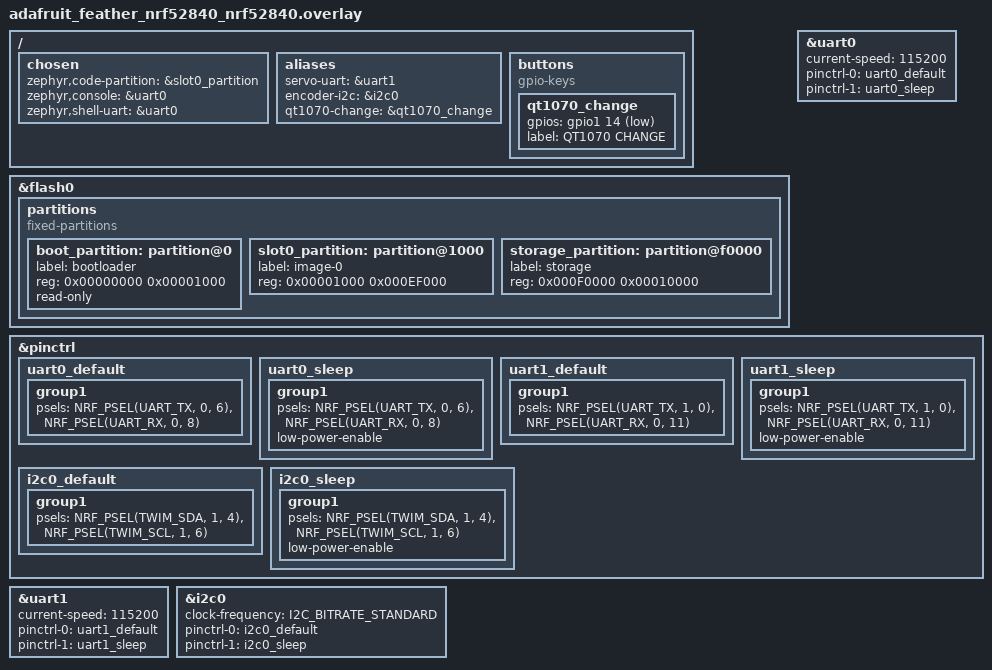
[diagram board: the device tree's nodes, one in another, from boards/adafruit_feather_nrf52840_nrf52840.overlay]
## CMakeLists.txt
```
cmake_minimum_required(VERSION 3.20.0)
find_package(Zephyr REQUIRED HINTS $ENV{ZEPHYR_BASE})
project(follower)

target_sources(app PRIVATE 
    src/main.c
    src/i2c_devices.c
    src/follower_transport.c
    src/controller_follower_protocol.cpp
)

include_directories(
    ${CMAKE_SOURCE_DIR}/inc
)
```

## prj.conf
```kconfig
# ---- Logging ----
CONFIG_LOG=y
CONFIG_LOG_BACKEND_UART=y
CONFIG_UART_CONSOLE=y
CONFIG_CONSOLE=y
CONFIG_LOG_MODE_IMMEDIATE=y

# ---- FPU -----
CONFIG_FPU=y
CONFIG_FPU_SHARING=y

# ---- Serial / UART ----
CONFIG_SERIAL=y
CONFIG_UART_ASYNC_API=y
CONFIG_UART_ASYNC_RX_HELPER=y
CONFIG_UART_LINE_CTRL=y
CONFIG_UART_INTERRUPT_DRIVEN=y
CONFIG_UART_0_INTERRUPT_DRIVEN=y
CONFIG_UART_1_INTERRUPT_DRIVEN=y

# ---- Bluetooth core ----
CONFIG_BT=y
CONFIG_BT_PERIPHERAL=y
CONFIG_BT_DEVICE_NAME="Follower"
CONFIG_BT_DEVICE_APPEARANCE=0

# ---- Nordic UART Service ----
CONFIG_BT_NUS=y

# ---- Buffer tuning ----
CONFIG_BT_BUF_ACL_TX_SIZE=251
CONFIG_BT_BUF_ACL_RX_SIZE=251
CONFIG_BT_L2CAP_TX_MTU=247
CONFIG_BT_BUF_ACL_TX_COUNT=3
CONFIG_BT_ATT_PREPARE_COUNT=4

# ---- Kernel ----
CONFIG_HEAP_MEM_POOL_SIZE=2048
CONFIG_MAIN_STACK_SIZE=2048
CONFIG_SYSTEM_WORKQUEUE_STACK_SIZE=2048

# ---- Devicetree ----
CONFIG_USE_DT_CODE_PARTITION=y

# ---- I2C ----
CONFIG_I2C=y

# ---- GPIO ----
CONFIG_GPIO=y

# ---- MISC ---- 
CONFIG_PRINTK_SYNC=y
```

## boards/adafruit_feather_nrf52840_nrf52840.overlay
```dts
/*
 * nice!nano / Feather nRF52840 Express — application overlay
 */

/* ---- 1. Flash partition table ---- */
/delete-node/ &boot_partition;
/delete-node/ &slot0_partition;
/delete-node/ &slot1_partition;
/delete-node/ &storage_partition;

/ {
    chosen {
        zephyr,code-partition = &slot0_partition;
        zephyr,console        = &uart0;
        zephyr,shell-uart     = &uart0;
    };

    aliases {
        servo-uart = &uart1;
        encoder-i2c = &i2c0;
    };
};

&flash0 {
    partitions {
        compatible = "fixed-partitions";
        #address-cells = <1>;
        #size-cells = <1>;
        ranges;

        boot_partition: partition@0 {
            label = "bootloader";
            reg = <0x00000000 0x00001000>;
            read-only;
        };

        slot0_partition: partition@1000 {
            label = "image-0";
            reg = <0x00001000 0x000EF000>;
        };

        storage_partition: partition@f0000 {
            label = "storage";
            reg = <0x000F0000 0x00010000>;
        };
    };
};

/* ---- 2. Hardware UART0 on D0/D1 (P0.08 RX / P0.06 TX) for logging ---- */
&uart0 {
    status = "okay";
    current-speed = <115200>;
    pinctrl-0 = <&uart0_default>;
    pinctrl-1 = <&uart0_sleep>;
    pinctrl-names = "default", "sleep";
};

&pinctrl {
    uart0_default: uart0_default {
        group1 {
            psels = <NRF_PSEL(UART_TX, 0, 6)>,
                    <NRF_PSEL(UART_RX, 0, 8)>;
        };
    };
    uart0_sleep: uart0_sleep {
        group1 {
            psels = <NRF_PSEL(UART_TX, 0, 6)>,
                    <NRF_PSEL(UART_RX, 0, 8)>;
            low-power-enable;
        };
    };
};

&uart1 {
    status = "okay";
    current-speed = <115200>;
    pinctrl-0 = <&uart1_default>;
    pinctrl-1 = <&uart1_sleep>;
    pinctrl-names = "default", "sleep";
};

&pinctrl {
    uart1_default: uart1_default {
        group1 {
            psels = <NRF_PSEL(UART_TX, 1, 0)>,
                    <NRF_PSEL(UART_RX, 0, 11)>;
        };
    };
    uart1_sleep: uart1_sleep {
        group1 {
            psels = <NRF_PSEL(UART_TX, 1, 0)>,
                    <NRF_PSEL(UART_RX, 0, 11)>;
            low-power-enable;
        };
    };
};

/* ---- Hardware I2C0 on P0.20 (SDA) / P0.22 (SCL) for mag encoders/touch---- */
&i2c0 {
    status = "okay";
    clock-frequency = <I2C_BITRATE_STANDARD>;
    pinctrl-0 = <&i2c0_default>;
    pinctrl-1 = <&i2c0_sleep>;
    pinctrl-names = "default", "sleep";
};

&pinctrl {
    i2c0_default: i2c0_default {
        group1 {
            psels = <NRF_PSEL(TWIM_SDA, 1, 4)>,
                    <NRF_PSEL(TWIM_SCL, 1, 6)>;
        };
    };
    i2c0_sleep: i2c0_sleep {
        group1 {
            psels = <NRF_PSEL(TWIM_SDA, 1, 4)>,
                    <NRF_PSEL(TWIM_SCL, 1, 6)>;
            low-power-enable;
        };
    };
};


/ {
    buttons {
        compatible = "gpio-keys";
        qt1070_change: qt1070_change {
            gpios = <&gpio1 14 (GPIO_PULL_UP | GPIO_ACTIVE_LOW)>;
            label = "QT1070 CHANGE";
        };
    };
    aliases {
        qt1070-change = &qt1070_change;
    };
};
```

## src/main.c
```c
#include <zephyr/kernel.h>
#include <zephyr/device.h>
#include <zephyr/drivers/uart.h>
#include <zephyr/drivers/gpio.h>
#include <zephyr/logging/log.h>
#include <zephyr/bluetooth/bluetooth.h>
#include <zephyr/bluetooth/conn.h>
#include <zephyr/bluetooth/gap.h>
#include <bluetooth/services/nus.h>
#include <stdio.h>
#include "i2c_devices.h"
#include "math.h"
#include "controller_follower_protocol.h"
#include "follower_transport.h"

LOG_MODULE_REGISTER(main, LOG_LEVEL_INF);

/* ---------------  Prototype declarations ------- */
static void lx16a_send_packet(uint8_t id, uint8_t len, uint8_t cmd, uint8_t ahb, uint8_t alb, uint16_t time);

/* ---------------- Hardware UART ---------------- */
#define UART_DEVICE_NODE DT_CHOSEN(zephyr_console)
static const struct device *uart_dev = DEVICE_DT_GET(DT_ALIAS(servo_uart));

#define UART_BUF_SIZE 256
static uint8_t uart_rx_buf[UART_BUF_SIZE];

static void uart_cb(const struct device *dev, struct uart_event *evt, void *user_data);
#define NUM_SERVOS    5

/* ---------------- UART callback ---------------- */
static void uart_cb(const struct device *dev, struct uart_event *evt, void *user_data)
{
    switch (evt->type) {
    case UART_RX_RDY:
        if(bt_is_ready()){
            LOG_INF("UART RX %d bytes", evt->data.rx.len);
            bt_nus_send(NULL, &evt->data.rx.buf[evt->data.rx.offset], evt->data.rx.len);
        }
        break;

    case UART_RX_BUF_REQUEST:
        uart_rx_buf_rsp(dev, uart_rx_buf, sizeof(uart_rx_buf));
        break;

    case UART_RX_BUF_RELEASED:
        break;

    case UART_TX_DONE:
        break;

    case UART_TX_ABORTED:
        LOG_WRN("UART TX aborted");
        break;

    default:
        break;
    }
}

/* ---------------- QT1070 CHANGE PIN ---------------- */
static const struct gpio_dt_spec qt_change = GPIO_DT_SPEC_GET(DT_ALIAS(qt1070_change), gpios);

static struct gpio_callback qt_cb;

static void qt_change_handler(const struct device *port,
                              struct gpio_callback *cb, uint32_t pins)
{
    uint8_t detection = 0;
    qt1070_read_status(&detection, NULL);
    LOG_INF("Touch interrupt: 0x%02X", detection);
}

/* ---------------- BLE NUS callbacks ---------------- */
static void nus_receive_cb(struct bt_conn *conn,
                            const uint8_t *data,
                            uint16_t len)
{
    ARG_UNUSED(conn);
    if (len < offsetof(protocol_frame_t, payload)) {
        printk("NUS RX: short frame (%u)\n", len);
        return;
    }

    protocol_frame_t frame;
    memset(&frame, 0, sizeof(frame));

    /* Copy the header */
    memcpy(&frame, data, offsetof(protocol_frame_t, payload));

    if (frame.start_byte != PROTO_START_BYTE) {
        printk("NUS RX: bad start byte 0x%02X\n", frame.start_byte);
        return;
    }
    if (frame.payload_length > PROTO_MAX_PAYLOAD_SIZE) {
        printk("NUS RX: payload too long (%u)\n", frame.payload_length);
        return;
    }

    size_t expected = frame_total_size(&frame);
    if (len < expected) {
        printk("NUS RX: truncated frame (got %u, need %u)\n",
               len, (unsigned)expected);
        return;
    }

    /* Copy payload and CRC */
    memcpy(frame.payload, data + offsetof(protocol_frame_t, payload),
           frame.payload_length);
    memcpy(&frame.crc,
           data + offsetof(protocol_frame_t, payload) + frame.payload_length,
           sizeof(frame.crc));

    if (!frame_verify_crc(&frame)) {
        printk("NUS RX: CRC mismatch\n");
        return;
    }

    if (frame.type != MSG_COMMAND_SERVO) {
        printk("NUS RX: unexpected type 0x%02X\n", frame.type);
        return;
    }
    if (frame.payload_length < sizeof(servo_command_payload_t)) {
        printk("NUS RX: short servo payload\n");
        return;
    }

    for (int i = 0; i < NUM_SERVOS; i++){
        printk("Sending 0x%02x", frame.payload[i]);
        lx16a_send_packet(i+1, 7, 1, frame.payload[i*2], frame.payload[(i*2)+1], 1000);
    }
}



static struct bt_nus_cb nus_cbs = {
    .received = nus_receive_cb,
};

/* ---------------- Connection callbacks ---------------- */
static void connected(struct bt_conn *conn, uint8_t err)
{
    if (err) {
        LOG_ERR("Connection failed (err %u)", err);
        return;
    }
    LOG_INF("BLE connected");
}

static void disconnected(struct bt_conn *conn, uint8_t reason)
{
    LOG_INF("BLE disconnected (reason %u)", reason);
}

BT_CONN_CB_DEFINE(conn_callbacks) = {
    .connected    = connected,
    .disconnected = disconnected,
};

/* ---------------- Advertising data ---------------- */
static const struct bt_data ad[] = {
    BT_DATA_BYTES(BT_DATA_FLAGS, (BT_LE_AD_GENERAL | BT_LE_AD_NO_BREDR)),
    BT_DATA(BT_DATA_NAME_COMPLETE, CONFIG_BT_DEVICE_NAME,
            sizeof(CONFIG_BT_DEVICE_NAME) - 1),
};

static const struct bt_data sd[] = {
    /* Uses the raw-byte UUID macro */
    BT_DATA_BYTES(BT_DATA_UUID128_ALL, BT_UUID_NUS_VAL),
};

/* Explicit adv parameters */
static const struct bt_le_adv_param adv_param =
    BT_LE_ADV_PARAM_INIT(BT_LE_ADV_OPT_CONN,
                         BT_GAP_ADV_FAST_INT_MIN_2,
                         BT_GAP_ADV_FAST_INT_MAX_2,
                         NULL);

/* ---------------- BT ready callback ---------------- */
static void bt_ready(int err)
{
    if (err) {
        LOG_ERR("Bluetooth init failed (err %d)", err);
        return;
    }
    LOG_INF("Bluetooth initialized");

    err = bt_nus_init(&nus_cbs);
    if (err) {
        LOG_ERR("NUS init failed (err %d)", err);
        return;
    }

    err = bt_le_adv_start(&adv_param, ad, ARRAY_SIZE(ad),
                          sd, ARRAY_SIZE(sd));
    if (err) {
        LOG_ERR("Advertising failed to start (err %d)", err);
        return;
    }
    LOG_INF("Advertising started as \"%s\"", CONFIG_BT_DEVICE_NAME);
}

static void sensor_thread(void *a, void *b, void *c)
{
    LOG_INF("Sensor Thread started");
    uint8_t detection = 0;
    uint16_t angle = 0;

    k_sleep(K_MSEC(200));
    for (;;) {
        if (qt1070_read_status(&detection, NULL) == 0 && detection) {
            LOG_INF("Touch: 0x%02X", detection);
        }
        if (as5600_read_angle(AS5600_I2C_ADDR, &angle) == 0) {
            /* use angle */
        }
        k_sleep(K_MSEC(20));
    }
}

K_THREAD_STACK_DEFINE(sensor_stack, 4096);
static struct k_thread sensor_thread_data;

/* ----------- SERVO PACKET FUNCTION ------------- */
static void lx16a_send_packet(uint8_t id, uint8_t len, uint8_t cmd, uint8_t ahb, uint8_t alb, uint16_t time) {
    // Packet format: 0x55 0x55 [ID] [LEN=7] CMD [PARAM_1] ... [PARAM_N]  [CHECKSUM]
    uint8_t servo_packet[10];

    servo_packet[0] = 0x55;
    servo_packet[1] = 0x55;
    servo_packet[2] = id;
    servo_packet[3] = len;
    servo_packet[4] = cmd;
    servo_packet[5] = alb;
    servo_packet[6] = ahb;
    servo_packet[7] = time & 0xFF;
    servo_packet[8] = (time >> 8) & 0xFF;
    servo_packet[9] = 0x00;

    // Calculate checksum (summation of bytes 2-8)
    uint8_t checksum = 0;
    for (int i = 2; i < 9; i++) {
        checksum += servo_packet[i];
    }
    servo_packet[9] = ~checksum; 

    printk("packet contents: %02X %02X %02X %02X %02X %02X %02X %02X %02X %02X\n", servo_packet[0], servo_packet[1],
                          servo_packet[2], servo_packet[3], servo_packet[4], servo_packet[5], servo_packet[6], servo_packet[7], servo_packet[8],
                        servo_packet[9]);
    
    /* Send over UART */
    for (int i = 0; i < 10; i++) {
        uart_poll_out(uart_dev, servo_packet[i]);
    }

    /* Inter-packet delay */
    k_msleep(5);

    return;

}

/**
  * @brief Home LX-16A servos upon startup 
  * @param channel Channel number (0-4 for servos 1-5)
  * @return 12-bit angle value (0-4095)
  */
void lx16a_home(void) {
  // home servos when loop starts
    printk("Homing servos...\n");
    lx16a_send_packet(254, 7, 1, 0x00, 0x00, 1000);
    k_msleep(1000);

    lx16a_send_packet(254, 7, 1, 0x00, 0x64, 1000);
    k_msleep(1000);

    lx16a_send_packet(254, 7, 1, 0x00, 0x00, 2000);
    k_msleep(1000);

    return;
  
}



/* ---------------- main() ---------------- */
int main(void)
{
    printk("PRINTK: main() reached\n");

    int err;

    printk("STEP 1: i2c readiness check\n");
    /* 1. Check peripherals are ready */
    if (!device_is_ready(DEVICE_DT_GET(DT_NODELABEL(i2c0)))) {
        LOG_ERR("I2C not ready");
        return -1;
    }
    
    printk("STEP 2: uart readiness check\n");
    if (!device_is_ready(DEVICE_DT_GET(DT_ALIAS(servo_uart)))) {
        LOG_ERR("UART not ready");
        return -1;
    }

    /* 2. Initialize I2C devices */
    printk("STEP 3: qt1070_init\n");
    err = qt1070_init();
    if (err) {
        LOG_ERR("QT1070 init failed (%d)", err);
        /* keep going — other devices may work */
    }
    printk("STEP 3 done: err=%d\n", err);

    printk("STEP 4: as5600_init\n");
    err = as5600_init(AS5600_I2C_ADDR);
    if (err) {
        LOG_WRN("AS5600 not found (%d)", err);
    }
    printk("STEP 4 done: err=%d\n", err);

    printk("STEP 5: uart_callback_set\n");
    uart_callback_set(DEVICE_DT_GET(DT_ALIAS(servo_uart)), uart_cb, NULL);

    printk("STEP 6: uart_rx_enable\n");
    uart_irq_rx_enable(DEVICE_DT_GET(DT_ALIAS(servo_uart)));

    printk("STEP 7: bt_enable\n");
    /* 4. Bring up Bluetooth */
    err = bt_enable(bt_ready);
    if (err) {
        LOG_ERR("bt_enable failed (err %d)", err);
        return -1;
    }
    printk("STEP 7 done: err=%d\n", err);

    LOG_INF("Ready. UART<->BLE bridge running.");

    printk("STEP 8: home servos\n");
    lx16a_home();
    k_sleep(K_MSEC(20));

    printk("STEP 9: create sensor thread\n");

    /* sensor thread*/
    k_thread_create(&sensor_thread_data, sensor_stack,
        K_THREAD_STACK_SIZEOF(sensor_stack),
        sensor_thread, NULL, NULL, NULL,
        5, 0, K_FOREVER);

    for (;;) {
        k_sleep(K_FOREVER);
    }
}
```

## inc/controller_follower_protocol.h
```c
#ifndef CONTROLLER_FOLLOWER_PROTOCOL_H
#define CONTROLLER_FOLLOWER_PROTOCOL_H

#include <stdint.h>
#include <stddef.h>

#ifdef __cplusplus
extern "C" {
#endif

/* ── Constants ──────────────────────────────────────────────────────────── */

#define PROTO_START_BYTE        0xAA
#define PROTO_CRC_INITIAL       0xFFFF
#define PROTO_CRC_POLYNOMIAL    0x1021
#define PROTO_MAX_PAYLOAD_SIZE  128
#define PROTO_MAX_SERVOS        12

/* ── Message types ──────────────────────────────────────────────────────── */

typedef enum {
    MSG_COMMAND_SERVO   = 0x01,   /* controller → follower */
    MSG_FEEDBACK_HAPTIC = 0x02,   /* follower → controller */
    MSG_FEEDBACK_STATE  = 0x03    /* follower → controller */
} message_type_t;

/* ── Packed payloads ────────────────────────────────────────────────────── */

#pragma pack(push, 1)

typedef struct {
    uint8_t  num_servos;
    uint16_t positions[PROTO_MAX_SERVOS];
    uint16_t duration_ms;
    uint8_t  flags;
} servo_command_payload_t;

typedef struct {
    float    force_magnitude;
    float    frequency_hz;
    uint16_t duration_ms;
    uint8_t  flags;
} haptic_feedback_payload_t;

typedef struct {
    float    battery_voltage;
    float    temperature_celsius;
    uint16_t error_code;
    float    current_positions[PROTO_MAX_SERVOS];
    float    velocities[PROTO_MAX_SERVOS];
} follower_state_payload_t;

typedef struct {
    uint8_t  start_byte;
    uint8_t  type;
    uint16_t sequence;
    uint32_t timestamp_ms;
    uint16_t payload_length;
    uint8_t  payload[PROTO_MAX_PAYLOAD_SIZE];
    uint16_t crc;
} protocol_frame_t;

#pragma pack(pop)

/* ── Compile-time size checks ───────────────────────────────────────────── */

#if defined(__STDC_VERSION__) && __STDC_VERSION__ >= 201112L
_Static_assert(sizeof(servo_command_payload_t)   <= PROTO_MAX_PAYLOAD_SIZE,
               "servo_command_payload_t too large");
_Static_assert(sizeof(haptic_feedback_payload_t) <= PROTO_MAX_PAYLOAD_SIZE,
               "haptic_feedback_payload_t too large");
_Static_assert(sizeof(follower_state_payload_t)  <= PROTO_MAX_PAYLOAD_SIZE,
               "follower_state_payload_t too large");
#endif

/* ── CRC helpers (platform-independent) ─────────────────────────────────── */

uint16_t crc16(const uint8_t *data, size_t len);
uint16_t compute_frame_crc(const protocol_frame_t *frame);

/* ── Frame helpers ──────────────────────────────────────────────────────── */

/* Returns the total number of bytes a frame occupies on the wire. */
size_t frame_total_size(const protocol_frame_t *frame);

/* Fill header + copy payload + compute CRC.
 * Returns true on success. */
int frame_build(protocol_frame_t *frame,
                uint8_t type,
                uint16_t sequence,
                uint32_t timestamp_ms,
                const void *payload,
                uint16_t payload_length);

/* Validate CRC. Returns true if valid. */
int frame_verify_crc(const protocol_frame_t *frame);

#ifdef __cplusplus
}
#endif

#endif /* CONTROLLER_FOLLOWER_PROTOCOL_H */
```

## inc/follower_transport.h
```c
#ifndef FOLLOWER_TRANSPORT_H
#define FOLLOWER_TRANSPORT_H

#include "controller_follower_protocol.h"
#include <zephyr/bluetooth/conn.h>

#ifdef __cplusplus
extern "C" {
#endif

static struct bt_conn *current_conn;

/* Must be called once, before advertising starts. Registers connection and NUS callbacks. */
int follower_transport_init(void);

/* Notify a payload back to the controller over the NUS TX characteristic.
 * Returns true if queued successfully. */
bool follower_transport_send(uint8_t type,
                             uint16_t sequence,
                             const void *payload,
                             uint16_t payload_length);

bool follower_send_haptic(const haptic_feedback_payload_t *fb,
                          uint16_t sequence);

bool follower_send_state(const follower_state_payload_t *state,
                         uint16_t sequence);


#ifdef __cplusplus
}
#endif

#endif /* FOLLOWER_TRANSPORT_H */
```

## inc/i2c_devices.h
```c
#ifndef I2C_DEVICES_H_
#define I2C_DEVICES_H_

#include <zephyr/kernel.h>
#include <stdint.h>

/* ---------------- AT42QT1070 ---------------- */
#define QT1070_I2C_ADDR              0x1B   /* 7-bit address */

/* Register map (AT42QT1070 datasheet §8) */
#define QT1070_REG_CHIP_ID           0x00   /* RO: reads 0x2E */
#define QT1070_REG_FW_VERSION        0x01   /* RO */
#define QT1070_REG_DETECTION_STATUS  0x02   /* RO: bit per key */
#define QT1070_REG_KEY_STATUS        0x03   /* RO: bit per key (filtered) */
#define QT1070_REG_KEY_SIGNAL_0      0x04   /* RO: 16-bit per key, big-endian */
#define QT1070_REG_KEY_REF_0         0x06   /* RO: 16-bit per key */
#define QT1070_REG_NTHR              0x10   /* RW: detection threshold */
#define QT1070_REG_CTRL              0x11   /* RW: control */
#define QT1070_REG_DATA0             0x12   /* RW: data byte 0 */
#define QT1070_REG_DATA1             0x13   /* RW: data byte 1 */
#define QT1070_REG_DATA2             0x14   /* RW: data byte 2 */
#define QT1070_REG_DATA3             0x15   /* RW: data byte 3 */
#define QT1070_REG_DATA4             0x16   /* RW: data byte 4 */
#define QT1070_REG_DATA5             0x17   /* RW: data byte 5 */
#define QT1070_REG_DI                0x18   /* RW: detection integrator */
#define QT1070_REG_GUARD_CHANNEL     0x19   /* RW: 0=off, 1..7 = channel X */

#define QT1070_CHIP_ID_VALUE         0x2E
#define QT1070_NUM_KEYS              7

int  qt1070_init(void);
int  qt1070_read_chip_id(uint8_t *id);
int  qt1070_read_status(uint8_t *detection, uint8_t *key_status);
bool qt1070_key_pressed(uint8_t key, uint8_t detection_byte);
int  qt1070_read_signal(uint8_t key, uint16_t *signal);
int  qt1070_set_nthr(uint8_t value);
int  qt1070_set_di(uint8_t value);
int  qt1070_set_guard_channel(uint8_t ch);

/* ---------------- Magnetic encoders ---------------- */
/* Example: AS5600 (12-bit magnetic rotary encoder) */
#define AS5600_I2C_ADDR              0x36
#define AS5600_REG_STATUS            0x0B
#define AS5600_REG_RAW_ANGLE_HI      0x0C   /* RO: 12-bit angle, big-endian */
#define AS5600_REG_RAW_ANGLE_LO      0x0D
#define AS5600_REG_ANGLE_HI          0x0E   /* RO: scaled angle */
#define AS5600_REG_ANGLE_LO          0x0F
#define AS5600_REG_AGC               0x1A   /* RO: automatic gain control */
#define AS5600_REG_MAGNITUDE_HI      0x1B   /* RO: 12-bit magnitude */
#define AS5600_REG_MAGNITUDE_LO      0x1C

int as5600_init(uint8_t i2c_addr);
int as5600_read_angle(uint8_t i2c_addr, uint16_t *angle);
int as5600_read_raw_angle(uint8_t i2c_addr, uint16_t *raw_angle);
int as5600_read_magnitude(uint8_t i2c_addr, uint16_t *magnitude);

#endif /* I2C_DEVICES_H_ */
```

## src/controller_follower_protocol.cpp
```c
#include "controller_follower_protocol.h"

#include <string.h>

uint16_t crc16(const uint8_t *data, size_t len)
{
    uint16_t crc = PROTO_CRC_INITIAL;
    for (size_t i = 0; i < len; ++i) {
        crc ^= (uint16_t)data[i] << 8;
        for (int b = 0; b < 8; ++b) {
            if (crc & 0x8000) {
                crc = (uint16_t)((crc << 1) ^ PROTO_CRC_POLYNOMIAL);
            } else {
                crc = (uint16_t)(crc << 1);
            }
        }
    }
    return crc;
}

size_t frame_total_size(const protocol_frame_t *frame)
{
    return offsetof(protocol_frame_t, payload)
         + frame->payload_length
         + sizeof(frame->crc);
}

uint16_t compute_frame_crc(const protocol_frame_t *frame)
{
    const uint8_t *p = (const uint8_t *)frame;

    /* header bytes after start_byte */
    uint16_t crc = crc16(p + 1, offsetof(protocol_frame_t, payload) - 1);

    /* payload bytes, continue the same CRC state */
    for (size_t i = 0; i < frame->payload_length; ++i) {
        crc ^= (uint16_t)frame->payload[i] << 8;
        for (int b = 0; b < 8; ++b) {
            crc = (crc & 0x8000) ? (uint16_t)((crc << 1) ^ PROTO_CRC_POLYNOMIAL)
                                 : (uint16_t)(crc << 1);
        }
    }
    return crc;
}

int frame_build(protocol_frame_t *frame,
                uint8_t type,
                uint16_t sequence,
                uint32_t timestamp_ms,
                const void *payload,
                uint16_t payload_length)
{
    if (!frame || payload_length > PROTO_MAX_PAYLOAD_SIZE) {
        return 0;
    }
    memset(frame, 0, sizeof(*frame));
    frame->start_byte     = PROTO_START_BYTE;
    frame->type           = type;
    frame->sequence       = sequence;
    frame->timestamp_ms   = timestamp_ms;
    frame->payload_length = payload_length;
    if (payload_length && payload) {
        memcpy(frame->payload, payload, payload_length);
    }
    frame->crc = compute_frame_crc(frame);
    return 1;
}

int frame_verify_crc(const protocol_frame_t *frame)
{
    if (frame->start_byte != PROTO_START_BYTE) {
        return 0;
    }
    if (frame->payload_length > PROTO_MAX_PAYLOAD_SIZE) {
        return 0;
    }
    return compute_frame_crc(frame) == frame->crc;
}
```

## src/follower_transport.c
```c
#include "follower_transport.h"

#include <string.h>
#include <zephyr/kernel.h>
#include <zephyr/bluetooth/bluetooth.h>
#include <zephyr/bluetooth/conn.h>
#include <zephyr/bluetooth/gatt.h>
#include <bluetooth/services/nus.h>
#include <zephyr/bluetooth/gap.h>

static struct bt_conn *current_conn;

/* ── Send ──────────────────────────────────────────────────────────────── */

bool follower_transport_send(uint8_t type,
                             uint16_t sequence,
                             const void *payload,
                             uint16_t payload_length)
{
    if (current_conn == NULL) {
        return false;
    }
    if (payload_length > PROTO_MAX_PAYLOAD_SIZE) {
        return false;
    }

    protocol_frame_t frame;
    if (!frame_build(&frame, type, sequence,
                     (uint32_t)k_uptime_get(),
                     payload, payload_length)) {
        return false;
    }

    size_t total = frame_total_size(&frame);

    /* bt_nus_send handles CCCD subscription checks and the notify call. */
    int err = bt_nus_send(current_conn, (const uint8_t *)&frame, total);
    return err == 0;
}

bool follower_send_haptic(const haptic_feedback_payload_t *fb, uint16_t sequence)
{
    return follower_transport_send(MSG_FEEDBACK_HAPTIC, sequence, fb, sizeof(*fb));
}

bool follower_send_state(const follower_state_payload_t *state, uint16_t sequence)
{
    return follower_transport_send(MSG_FEEDBACK_STATE, sequence, state, sizeof(*state));
}
```

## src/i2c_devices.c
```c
#include "i2c_devices.h"
#include <zephyr/device.h>
#include <zephyr/drivers/i2c.h>
#include <zephyr/logging/log.h>

LOG_MODULE_REGISTER(i2c_dev, LOG_LEVEL_INF);

/* Get I2C bus 0 from Devicetree (resolved at compile time) */
static const struct device *i2c_bus = DEVICE_DT_GET(DT_NODELABEL(i2c0));

/* ---------------- Helpers ---------------- */
static int i2c_write_reg(uint8_t dev_addr, uint8_t reg, uint8_t value)
{
    uint8_t buf[2] = { reg, value };
    return i2c_write(i2c_bus, buf, sizeof(buf), dev_addr);
}

static int i2c_read_reg(uint8_t dev_addr, uint8_t reg, uint8_t *value)
{
    return i2c_write_read(i2c_bus, dev_addr, &reg, 1, value, 1);
}

static int i2c_read_regs(uint8_t dev_addr, uint8_t reg, uint8_t *buf, size_t len)
{
    return i2c_write_read(i2c_bus, dev_addr, &reg, 1, buf, len);
}

/* ---------------- AT42QT1070 ---------------- */
int qt1070_init(void)
{
    uint8_t id = 0;
    int err = qt1070_read_chip_id(&id);
    if (err) {
        LOG_ERR("QT1070 not responding (err %d)", err);
        return err;
    }
    if (id != QT1070_CHIP_ID_VALUE) {
        LOG_ERR("QT1070 wrong chip ID: 0x%02X (expected 0x%02X)",
                id, QT1070_CHIP_ID_VALUE);
        return -EIO;
    }
    LOG_INF("QT1070 initialized, chip ID 0x%02X", id);
    return 0;
}

int qt1070_read_chip_id(uint8_t *id)
{
    return i2c_read_reg(QT1070_I2C_ADDR, QT1070_REG_CHIP_ID, id);
}

int qt1070_read_status(uint8_t *detection, uint8_t *key_status)
{
    /* The QT1070 supports multi-byte reads: read both registers in one shot */
    uint8_t buf[2];
    int err = i2c_read_regs(QT1070_I2C_ADDR,
                            QT1070_REG_DETECTION_STATUS,
                            buf, sizeof(buf));
    if (err) return err;
    if (detection)  *detection  = buf[0];
    if (key_status) *key_status = buf[1];
    return 0;
}

bool qt1070_key_pressed(uint8_t key, uint8_t detection_byte)
{
    if (key >= QT1070_NUM_KEYS) return false;
    return (detection_byte & (1 << key)) != 0;
}

int qt1070_read_signal(uint8_t key, uint16_t *signal)
{
    if (key >= QT1070_NUM_KEYS) return -EINVAL;
    uint8_t reg = QT1070_REG_KEY_SIGNAL_0 + (key * 2);
    uint8_t buf[2];
    int err = i2c_read_regs(QT1070_I2C_ADDR, reg, buf, 2);
    if (err) return err;
    /* Signal is a 16-bit big-endian value, only low 10 bits meaningful */
    *signal = ((uint16_t)buf[0] << 8) | buf[1];
    *signal &= 0x03FF;   /* 10-bit */
    return 0;
}

int qt1070_set_nthr(uint8_t value)
{
    return i2c_write_reg(QT1070_I2C_ADDR, QT1070_REG_NTHR, value);
}

int qt1070_set_di(uint8_t value)
{
    return i2c_write_reg(QT1070_I2C_ADDR, QT1070_REG_DI, value);
}

int qt1070_set_guard_channel(uint8_t ch)
{
    if (ch > 7) return -EINVAL;
    return i2c_write_reg(QT1070_I2C_ADDR, QT1070_REG_GUARD_CHANNEL, ch);
}

/* ---------------- AS5600 magnetic encoder ---------------- */
int as5600_init(uint8_t i2c_addr)
{
    uint8_t status = 0;
    int err = i2c_read_reg(i2c_addr, AS5600_REG_STATUS, &status);
    if (err) {
        LOG_ERR("AS5600 @0x%02X not responding (err %d)", i2c_addr, err);
        return err;
    }
    LOG_INF("AS5600 @0x%02X status=0x%02X", i2c_addr, status);
    return 0;
}

int as5600_read_angle(uint8_t i2c_addr, uint16_t *angle)
{
    uint8_t buf[2];
    int err = i2c_read_regs(i2c_addr, AS5600_REG_ANGLE_HI, buf, 2);
    if (err) return err;
    *angle = (((uint16_t)buf[0] << 8) | buf[1]) & 0x0FFF;  /* 12-bit */
    return 0;
}

int as5600_read_raw_angle(uint8_t i2c_addr, uint16_t *raw_angle)
{
    uint8_t buf[2];
    int err = i2c_read_regs(i2c_addr, AS5600_REG_RAW_ANGLE_HI, buf, 2);
    if (err) return err;
    *raw_angle = (((uint16_t)buf[0] << 8) | buf[1]) & 0x0FFF;
    return 0;
}

int as5600_read_magnitude(uint8_t i2c_addr, uint16_t *magnitude)
{
    uint8_t buf[2];
    int err = i2c_read_regs(i2c_addr, AS5600_REG_MAGNITUDE_HI, buf, 2);
    if (err) return err;
    *magnitude = (((uint16_t)buf[0] << 8) | buf[1]) & 0x0FFF;
    return 0;
}
```
